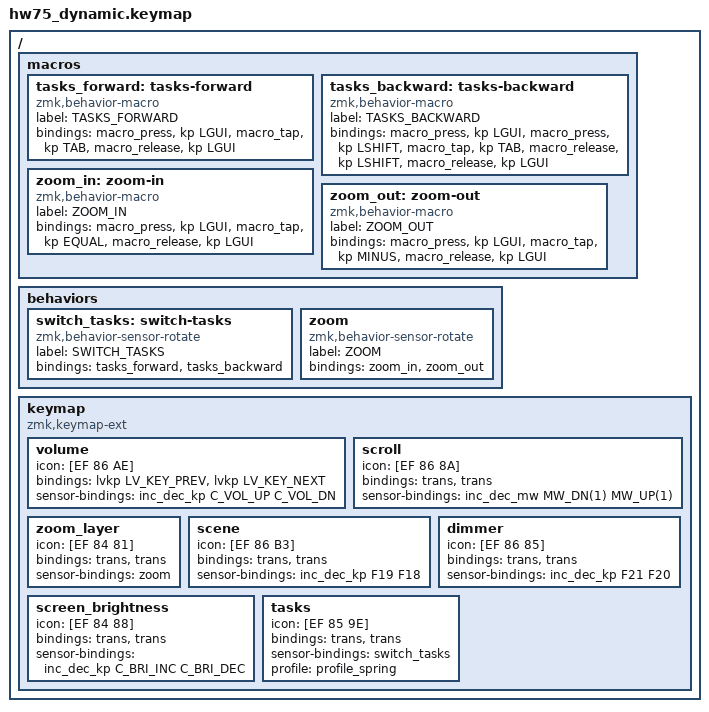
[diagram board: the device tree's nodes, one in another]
/*
 * Copyright (c) 2022 The ZMK Contributors
 * SPDX-License-Identifier: MIT
 */

#include <behaviors.dtsi>
#include <behaviors/lvgl_key_press.dtsi>
#include <behaviors/sensor_rotate_mouse_wheel.dtsi>
#include <dt-bindings/zmk/keys.h>
#include <dt-bindings/zmk/rgb.h>
#include <dt-bindings/zmk/lvgl.h>
#include <dt-bindings/zmk/mouse.h>

/ {
	macros {
		tasks_forward: tasks-forward {
			label = "TASKS_FORWARD";
			compatible = "zmk,behavior-macro";
			#binding-cells = <0>;
			bindings = <&macro_press   &kp LGUI>,
				   <&macro_tap     &kp TAB>,
				   <&macro_release &kp LGUI>;
		};

		tasks_backward: tasks-backward {
			label = "TASKS_BACKWARD";
			compatible = "zmk,behavior-macro";
			#binding-cells = <0>;
			bindings = <&macro_press   &kp LGUI>,
				   <&macro_press   &kp LSHIFT>,
				   <&macro_tap     &kp TAB>,
				   <&macro_release &kp LSHIFT>,
				   <&macro_release &kp LGUI>;
		};

		zoom_in: zoom-in {
			label = "ZOOM_IN";
			compatible = "zmk,behavior-macro";
			#binding-cells = <0>;
			bindings = <&macro_press   &kp LGUI>,
				   <&macro_tap     &kp EQUAL>,
				   <&macro_release &kp LGUI>;
		};

		zoom_out: zoom-out {
			label = "ZOOM_OUT";
			compatible = "zmk,behavior-macro";
			#binding-cells = <0>;
			bindings = <&macro_press   &kp LGUI>,
				   <&macro_tap     &kp MINUS>,
				   <&macro_release &kp LGUI>;
		};
	};

	behaviors {
		switch_tasks: switch-tasks {
			compatible = "zmk,behavior-sensor-rotate";
			label = "SWITCH_TASKS";
			#sensor-binding-cells = <0>;
			bindings = <&tasks_forward>, <&tasks_backward>;
		};

		zoom: zoom {
			compatible = "zmk,behavior-sensor-rotate";
			label = "ZOOM";
			#sensor-binding-cells = <0>;
			bindings = <&zoom_in>, <&zoom_out>;
		};
	};

	keymap {
		compatible = "zmk,keymap-ext", "zmk,keymap";

		volume {
			label = "音量";
			icon = [EF 86 AE];
			bindings = <&lvkp LV_KEY_PREV &lvkp LV_KEY_NEXT>;
			sensor-bindings = <&inc_dec_kp C_VOL_UP C_VOL_DN>;
		};

		scroll {
			label = "滚动";
			icon = [EF 86 8A];
			bindings = <&trans &trans>;
			sensor-bindings = <&inc_dec_mw MW_DN(1) MW_UP(1)>;
		};

		zoom_layer {
			label = "缩放";
			icon = [EF 84 81];
			bindings = <&trans &trans>;
			sensor-bindings = <&zoom>;
		};

		scene {
			label = "场景";
			icon = [EF 86 B3];
			bindings = <&trans &trans>;
			sensor-bindings = <&inc_dec_kp F19 F18>;
		};

		dimmer {
			label = "调光";
			icon = [EF 86 85];
			bindings = <&trans &trans>;
			sensor-bindings = <&inc_dec_kp F21 F20>;
		};

		screen_brightness {
			label = "屏幕";
			icon = [EF 84 88];
			bindings = <&trans &trans>;
			sensor-bindings = <&inc_dec_kp C_BRI_INC C_BRI_DEC>;
		};

		tasks {
			label = "窗口";
			icon = [EF 85 9E];
			bindings = <&trans &trans>;
			sensor-bindings = <&switch_tasks>;
			profile = <&profile_spring>;
		};
	};
};
